# SPC1169 register map
File version: 2022071043481212
CPU: cm4 r1p0, little endian, no MPU, FPU, 4 interrupt priority bits
Registers are 32-bit, read-write, reset 0x0 unless marked. A register's access mark holds for its fields unless they carry their own. Offsets are from the block's base; [hi:lo] are bit positions; {n}, {i} and the like mark numbered series; 'fields as' and 'values as' point back to an identical list.

## PWMCFG
Base 0x40002F00
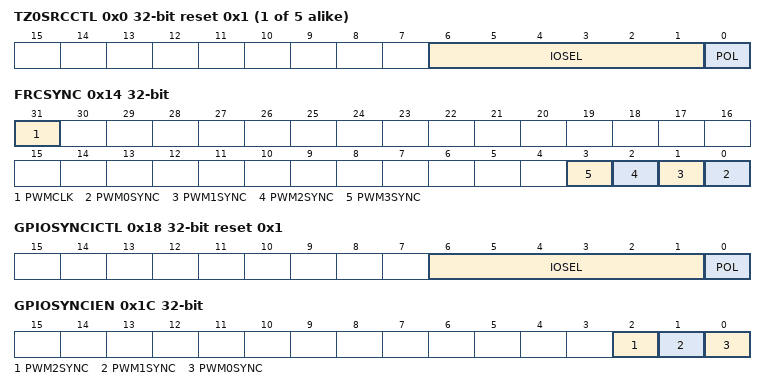
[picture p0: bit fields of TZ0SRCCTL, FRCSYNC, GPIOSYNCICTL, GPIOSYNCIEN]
{0x0+4i} TZ{i}SRCCTL reset 0x1 (i=0..4) — TZ{i} Source Control Register
  [6:1] IOSEL — GPIO number for TZ{i} event
  [0] POL — TZ{i} polarity
    0=ACTIVE_LOW (Active when low); 1=ACTIVE_HIGH (Active when high)
0x14 FRCSYNC — Global PWM Force Synchronization Register
  [31] PWMCLK — Software forced synchronization on clock for all PWMs
    0=NO_EFFECT (Write 0 has no effect and always read back 0); 1=FORCE (Write a 1 will force a SYNC on all PWM clocks. This bit is self-cleared)
  [n] PWM{n}SYNC (n=0..3) — Software forced synchronization on PWM{n}
    0=NO_EFFECT (Write 0 has no effect and always read back 0); 1=FORCE (Write a 1 will force a SYNC event on PWM{n}. This bit is self-cleared)
0x18 GPIOSYNCICTL reset 0x1 — GPIO PWMSYNCI Control Register
  [6:1] IOSEL — GPIO number for PWMSYNCI input
  [0] POL — PWMSYNCI input polarity
    values as TZ0SRCCTL.POL
0x1C GPIOSYNCIEN — GPIO Force PWMSYNCI Enable Register
  [all] fields
    0=DISABLE; 1=ENABLE
  [2] PWM2SYNC — Enable PWM2 synchronization by GPIO
  [1] PWM1SYNC — Enable PWM1 synchronization by GPIO
  [0] PWM0SYNC — Enable PWM0 synchronization by GPIO
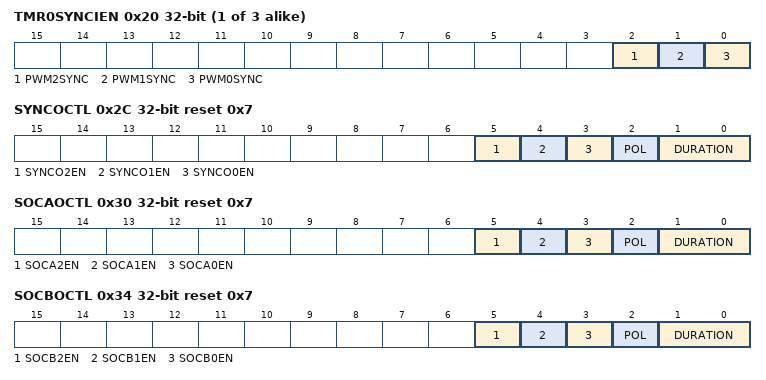
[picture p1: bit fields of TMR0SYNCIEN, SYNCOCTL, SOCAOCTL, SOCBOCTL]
{0x20+4i} TMR{i}SYNCIEN (i=0..2) — Timer {i} Force PWMSYNCI Enable Register
  [all] fields
    0=DISABLE; 1=ENABLE
  [2] PWM2SYNC — Enable PWM2 synchronization by Timer {i}
  [1] PWM1SYNC — Enable PWM1 synchronization by Timer {i}
  [0] PWM0SYNC — Enable PWM0 synchronization by Timer {i}
0x2C SYNCOCTL reset 0x7 — PWMSYNCO Control Register
  [5] SYNCO2EN — Enable PWM2SYNCO output to the pin
    0=DISABLE; 1=ENABLE
  [4] SYNCO1EN — Enable PWM1SYNCO output to the pin
    0=DISABLE; 1=ENABLE
  [3] SYNCO0EN — Enable PWM0SYNCO output to the pin
    0=DISABLE; 1=ENABLE
  [2] POL — Polarity of PWMSYNCO to the pin
    values as TZ0SRCCTL.POL
  [1:0] DURATION — Pulse duration of PWMSYNCO to the pin
    0=4_PWM_CLK (Duration of PWMSYNCO pulse to the pin is 4 PWM clocks); 1=8_PWM_CLK (Duration of PWMSYNCO pulse to the pin is 8 PWM clocks); 2=16_PWM_CLK (Duration of PWMSYNCO pulse to the pin is 16 PWM clocks); 3=32_PWM_CLK (Duration of PWMSYNCO pulse to the pin is 32 PWM clocks)
0x30 SOCAOCTL reset 0x7 — PWMSOCA Output Control Register
  [5] SOCA2EN — Enable PWM2SOCA output to the pin
    0=DISABLE; 1=ENABLE
  [4] SOCA1EN — Enable PWM1SOCA output to the pin
    0=DISABLE; 1=ENABLE
  [3] SOCA0EN — Enable PWM0SOCA output to the pin
    0=DISABLE; 1=ENABLE
  [2] POL — Polarity of PWMSOCA output to the pin
    values as TZ0SRCCTL.POL
  [1:0] DURATION — Pulse duration of PWMSOCA output to the pin
    0=4_PWM_CLK (Duration of PWMSOCA pulse to the pin is 4 PWM clocks); 1=8_PWM_CLK (Duration of PWMSOCA pulse to the pin is 8 PWM clocks); 2=16_PWM_CLK (Duration of PWMSOCA pulse to the pin is 16 PWM clocks); 3=32_PWM_CLK (Duration of PWMSOCA pulse to the pin is 32 PWM clocks)
0x34 SOCBOCTL reset 0x7 — PWMSOCB Output Control Register
  [5] SOCB2EN — Enable PWM2SOCB output to the pin
    0=DISABLE; 1=ENABLE
  [4] SOCB1EN — Enable PWM1SOCB output to the pin
    0=DISABLE; 1=ENABLE
  [3] SOCB0EN — Enable PWM0SOCB output to the pin
    0=DISABLE; 1=ENABLE
  [2] POL — Polarity of PWMSOCB output to the pin
    values as TZ0SRCCTL.POL
  [1:0] DURATION — Pulse duration of PWMSOCB output to the pin
    0=4_PWM_CLK (Duration of PWMSOCB pulse to the pin is 4 PWM clocks); 1=8_PWM_CLK (Duration of PWMSOCB pulse to the pin is 8 PWM clocks); 2=16_PWM_CLK (Duration of PWMSOCB pulse to the pin is 16 PWM clocks); 3=32_PWM_CLK (Duration of PWMSOCB pulse to the pin is 32 PWM clocks)
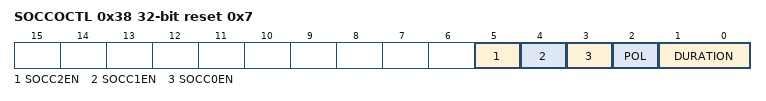
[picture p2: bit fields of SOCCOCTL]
0x38 SOCCOCTL reset 0x7 — PWMSOCC Output Control Register
  [5] SOCC2EN — Enable PWM2SOCC output to the pin
    0=DISABLE; 1=ENABLE
  [4] SOCC1EN — Enable PWM1SOCC output to the pin
    0=DISABLE; 1=ENABLE
  [3] SOCC0EN — Enable PWM0SOCC output to the pin
    0=DISABLE; 1=ENABLE
  [2] POL — Polarity of PWMSOCC output to the pin
    values as TZ0SRCCTL.POL
  [1:0] DURATION — Pulse duration of PWMSOCC output to the pin
    0=4_PWM_CLK (Duration of PWMSOCC pulse to the pin is 4 PWM clocks); 1=8_PWM_CLK (Duration of PWMSOCC pulse to the pin is 8 PWM clocks); 2=16_PWM_CLK (Duration of PWMSOCC pulse to the pin is 16 PWM clocks); 3=32_PWM_CLK (Duration of PWMSOCC pulse to the pin is 32 PWM clocks)
0x3C PWMCFGREGKEY reset 0x1ACCE551 — PWMCFG Register Write-Allow Key Register
  [31:0] KEY — Write 0x1ACCE551 to unlock protected PWMCFG registers
